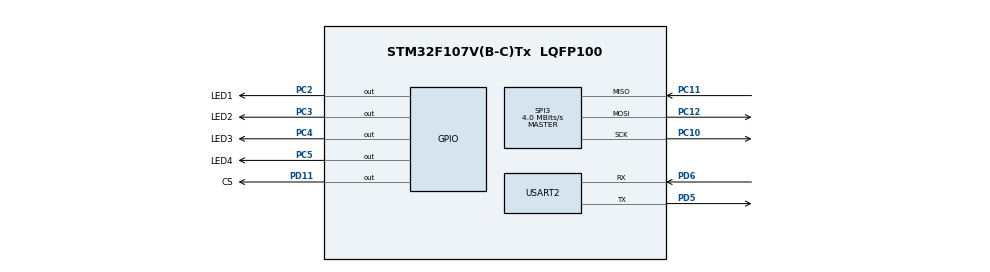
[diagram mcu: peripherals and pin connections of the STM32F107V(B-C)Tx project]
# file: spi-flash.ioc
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Mcu.Family=STM32F1
Mcu.Name=STM32F107V(B-C)Tx
Mcu.Package=LQFP100
NVIC.PriorityGroup=NVIC_PRIORITYGROUP_4
OSC_IN.Mode=HSE-External-Oscillator
OSC_IN.Signal=RCC_OSC_IN
OSC_OUT.Mode=HSE-External-Oscillator
OSC_OUT.Signal=RCC_OSC_OUT
PA13.Mode=Serial_Wire
PA13.Signal=SYS_JTMS-SWDIO
PA14.Mode=Serial_Wire
PA14.Signal=SYS_JTCK-SWCLK
PC10.Mode=Full_Duplex_Master
PC10.Signal=SPI3_SCK
PC11.Mode=Full_Duplex_Master
PC11.Signal=SPI3_MISO
PC12.Mode=Full_Duplex_Master
PC12.Signal=SPI3_MOSI
PC2.GPIO_Label=LED1
PC2.Signal=GPIO_Output
PC3.GPIO_Label=LED2
PC3.Signal=GPIO_Output
PC4.GPIO_Label=LED3
PC4.Signal=GPIO_Output
PC5.GPIO_Label=LED4
PC5.Signal=GPIO_Output
PD11.GPIO_Label=CS
PD11.Signal=GPIO_Output
PD5.Mode=Asynchronous
PD5.Signal=USART2_TX
PD6.Mode=Asynchronous
PD6.Signal=USART2_RX
ProjectManager.HeapSize=0x2000
ProjectManager.StackSize=0x4000
ProjectManager.TargetToolchain=MDK-ARM V5
RCC.USBFreq_Value=10666666.666666666
SPI3.BaudRatePrescaler=SPI_BAUDRATEPRESCALER_2
SPI3.CLKPhase=SPI_PHASE_2EDGE
SPI3.CLKPolarity=SPI_POLARITY_HIGH
SPI3.CalculateBaudRate=4.0 MBits/s
SPI3.DataSize=SPI_DATASIZE_8BIT
SPI3.Direction=SPI_DIRECTION_2LINES
SPI3.FirstBit=SPI_FIRSTBIT_MSB
SPI3.Mode=SPI_MODE_MASTER
SPI3.VirtualType=VM_MASTER
USART2.VirtualMode=VM_ASYNC
board=spi-flash

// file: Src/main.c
/**
  ******************************************************************************
  * @file           : main.c
  * @brief          : Main program body
  ******************************************************************************
  ** This notice applies to any and all portions of this file
  * that are not between comment pairs USER CODE BEGIN and
  * USER CODE END. Other portions of this file, whether
  * inserted by the user or by software development tools
  * are owned by their respective copyright owners.
  *
  * COPYRIGHT(c) 2018 STMicroelectronics
  *
  * Redistribution and use in source and binary forms, with or without modification,
  * are permitted provided that the following conditions are met:
  *   1. Redistributions of source code must retain the above copyright notice,
  *      this list of conditions and the following disclaimer.
  *   2. Redistributions in binary form must reproduce the above copyright notice,
  *      this list of conditions and the following disclaimer in the documentation
  *      and/or other materials provided with the distribution.
  *   3. Neither the name of STMicroelectronics nor the names of its contributors
  *      may be used to endorse or promote products derived from this software
  *      without specific prior written permission.
  *
  * THIS SOFTWARE IS PROVIDED BY THE COPYRIGHT HOLDERS AND CONTRIBUTORS "AS IS"
  * AND ANY EXPRESS OR IMPLIED WARRANTIES, INCLUDING, BUT NOT LIMITED TO, THE
  * IMPLIED WARRANTIES OF MERCHANTABILITY AND FITNESS FOR A PARTICULAR PURPOSE ARE
  * DISCLAIMED. IN NO EVENT SHALL THE COPYRIGHT HOLDER OR CONTRIBUTORS BE LIABLE
  * FOR ANY DIRECT, INDIRECT, INCIDENTAL, SPECIAL, EXEMPLARY, OR CONSEQUENTIAL
  * DAMAGES (INCLUDING, BUT NOT LIMITED TO, PROCUREMENT OF SUBSTITUTE GOODS OR
  * SERVICES; LOSS OF USE, DATA, OR PROFITS; OR BUSINESS INTERRUPTION) HOWEVER
  * CAUSED AND ON ANY THEORY OF LIABILITY, WHETHER IN CONTRACT, STRICT LIABILITY,
  * OR TORT (INCLUDING NEGLIGENCE OR OTHERWISE) ARISING IN ANY WAY OUT OF THE USE
  * OF THIS SOFTWARE, EVEN IF ADVISED OF THE POSSIBILITY OF SUCH DAMAGE.
  *
  ******************************************************************************
  */
#include "main.h"
#include "stm32f1xx_hal.h"

/* USER CODE BEGIN Includes */
#include "spi_flash.h"
#include "string.h"

/* USER CODE END Includes */

SPI_HandleTypeDef hspi3;

UART_HandleTypeDef huart2;

/* USER CODE BEGIN PV */
/* Private variables ---------------------------------------------------------*/

/* USER CODE END PV */

void SystemClock_Config(void);
static void MX_GPIO_Init(void);
static void MX_SPI3_Init(void);
static void MX_USART2_UART_Init(void);

/* USER CODE BEGIN PFP */
/* Private function prototypes -----------------------------------------------*/
void writeData(unsigned int PageAdr,unsigned char *buffer)
{
  Buffer_Write_Str(1,PageAdr,528,buffer);
  Buffer_To_Page(1,PageAdr);
}
void readData(unsigned int PageAdr,unsigned char *buffer)
{
  Page_To_Buffer(PageAdr,1);
  Buffer_Read_Str(1,PageAdr,528,buffer);
}
/* USER CODE END PFP */

int main(void)
{
  /* USER CODE BEGIN 1 */
	uint8_t buff[528];
  /* USER CODE END 1 */

  /* MCU Configuration----------------------------------------------------------*/

  /* Reset of all peripherals, Initializes the Flash interface and the Systick. */
  HAL_Init();

  /* Configure the system clock */
  SystemClock_Config();

  /* Initialize all configured peripherals */
  MX_GPIO_Init();
  MX_SPI3_Init();
  MX_USART2_UART_Init();
  /* USER CODE BEGIN 2 */

  HAL_GPIO_WritePin(CS_GPIO_Port, CS_Pin, GPIO_PIN_SET);

 Read_DF_status();
//
//	memset(buff,0x40,sizeof(buff));

//  writeData(10,buff);

//  //Buffer_Write_Enable(0,1);

//  memset(buff,0x00,sizeof(buff));

//  readData(10,buff);

//  Page_Erase(10);

//  readData(10,buff);

  /* USER CODE END 2 */

  /* Infinite loop */
  while (1)
  {
//    HAL_GPIO_WritePin(CS_GPIO_Port, CS_Pin, GPIO_PIN_SET);
//		HAL_Delay(2000);
//		HAL_GPIO_WritePin(CS_GPIO_Port, CS_Pin, GPIO_PIN_RESET);
//		HAL_Delay(2000);
  }

}

void SystemClock_Config(void)
{

  RCC_OscInitTypeDef RCC_OscInitStruct;
  RCC_ClkInitTypeDef RCC_ClkInitStruct;

    /**Initializes the CPU, AHB and APB busses clocks
    */
  RCC_OscInitStruct.OscillatorType = RCC_OSCILLATORTYPE_HSI;
  RCC_OscInitStruct.HSIState = RCC_HSI_ON;
  RCC_OscInitStruct.HSICalibrationValue = 16;
  RCC_OscInitStruct.PLL.PLLState = RCC_PLL_NONE;
  RCC_OscInitStruct.PLL2.PLL2State = RCC_PLL_NONE;
  if (HAL_RCC_OscConfig(&RCC_OscInitStruct) != HAL_OK)
  {
    _Error_Handler(__FILE__, __LINE__);
  }

    /**Initializes the CPU, AHB and APB busses clocks
    */
  RCC_ClkInitStruct.ClockType = RCC_CLOCKTYPE_HCLK|RCC_CLOCKTYPE_SYSCLK
                              |RCC_CLOCKTYPE_PCLK1|RCC_CLOCKTYPE_PCLK2;
  RCC_ClkInitStruct.SYSCLKSource = RCC_SYSCLKSOURCE_HSI;
  RCC_ClkInitStruct.AHBCLKDivider = RCC_SYSCLK_DIV1;
  RCC_ClkInitStruct.APB1CLKDivider = RCC_HCLK_DIV1;
  RCC_ClkInitStruct.APB2CLKDivider = RCC_HCLK_DIV1;

  if (HAL_RCC_ClockConfig(&RCC_ClkInitStruct, FLASH_LATENCY_0) != HAL_OK)
  {
    _Error_Handler(__FILE__, __LINE__);
  }

    /**Configure the Systick interrupt time
    */
  HAL_SYSTICK_Config(HAL_RCC_GetHCLKFreq()/1000);

    /**Configure the Systick
    */
  HAL_SYSTICK_CLKSourceConfig(SYSTICK_CLKSOURCE_HCLK);

    /**Configure the Systick interrupt time
    */
  __HAL_RCC_PLLI2S_ENABLE();

  /* SysTick_IRQn interrupt configuration */
  HAL_NVIC_SetPriority(SysTick_IRQn, 0, 0);
}

/* SPI3 init function */
static void MX_SPI3_Init(void)
{

  /* SPI3 parameter configuration*/
  hspi3.Instance = SPI3;
  hspi3.Init.Mode = SPI_MODE_MASTER;
  hspi3.Init.Direction = SPI_DIRECTION_2LINES;
  hspi3.Init.DataSize = SPI_DATASIZE_8BIT;
  hspi3.Init.CLKPolarity = SPI_POLARITY_HIGH;
  hspi3.Init.CLKPhase = SPI_PHASE_2EDGE;
  hspi3.Init.NSS = SPI_NSS_SOFT;
  hspi3.Init.BaudRatePrescaler = SPI_BAUDRATEPRESCALER_4;
  hspi3.Init.FirstBit = SPI_FIRSTBIT_MSB;
  hspi3.Init.TIMode = SPI_TIMODE_DISABLE;
  hspi3.Init.CRCCalculation = SPI_CRCCALCULATION_DISABLE;
  hspi3.Init.CRCPolynomial = 7;
  if (HAL_SPI_Init(&hspi3) != HAL_OK)
  {
    _Error_Handler(__FILE__, __LINE__);
  }

}

/* USART2 init function */
static void MX_USART2_UART_Init(void)
{

  huart2.Instance = USART2;
  huart2.Init.BaudRate = 115200;
  huart2.Init.WordLength = UART_WORDLENGTH_8B;
  huart2.Init.StopBits = UART_STOPBITS_1;
  huart2.Init.Parity = UART_PARITY_NONE;
  huart2.Init.Mode = UART_MODE_TX_RX;
  huart2.Init.HwFlowCtl = UART_HWCONTROL_NONE;
  huart2.Init.OverSampling = UART_OVERSAMPLING_16;
  if (HAL_UART_Init(&huart2) != HAL_OK)
  {
    _Error_Handler(__FILE__, __LINE__);
  }

}

/** Configure pins as
        * Analog
        * Input
        * Output
        * EVENT_OUT
        * EXTI
*/
static void MX_GPIO_Init(void)
{

  GPIO_InitTypeDef GPIO_InitStruct;

  /* GPIO Ports Clock Enable */
  __HAL_RCC_GPIOC_CLK_ENABLE();
  __HAL_RCC_GPIOD_CLK_ENABLE();
  __HAL_RCC_GPIOA_CLK_ENABLE();

  /*Configure GPIO pin Output Level */
  HAL_GPIO_WritePin(GPIOC, LED1_Pin|LED2_Pin|LED3_Pin|LED4_Pin, GPIO_PIN_RESET);

  /*Configure GPIO pin Output Level */
  HAL_GPIO_WritePin(CS_GPIO_Port, CS_Pin, GPIO_PIN_SET);

  /*Configure GPIO pins : LED1_Pin LED2_Pin LED3_Pin LED4_Pin */
  GPIO_InitStruct.Pin = LED1_Pin|LED2_Pin|LED3_Pin|LED4_Pin;
  GPIO_InitStruct.Mode = GPIO_MODE_OUTPUT_PP;
  GPIO_InitStruct.Speed = GPIO_SPEED_FREQ_LOW;
  HAL_GPIO_Init(GPIOC, &GPIO_InitStruct);

  /*Configure GPIO pin : CS_Pin */
  GPIO_InitStruct.Pin = CS_Pin;
  GPIO_InitStruct.Mode = GPIO_MODE_OUTPUT_PP;
  GPIO_InitStruct.Speed = GPIO_SPEED_FREQ_HIGH;
  HAL_GPIO_Init(CS_GPIO_Port, &GPIO_InitStruct);

}

void _Error_Handler(char *file, int line)
{
  while(1)
  {
  }
}

/************************ (C) COPYRIGHT STMicroelectronics *****END OF FILE****/
